# STM32MP21_CA35 register map
File version: 0.4
CPU: CM33 r0p1, little endian, MPU, FPU, vendor SysTick, 8 interrupt priority bits
Registers are 32-bit, read-write, reset 0x0 unless marked. A register's access mark holds for its fields unless they carry their own. Offsets are from the block's base; [hi:lo] are bit positions; {n}, {i} and the like mark numbered series; 'fields as' and 'values as' point back to an identical list.

## TIM15 — TIM15 address block description
Base 0x40250000
Same registers: TIM15_S 0x50250000
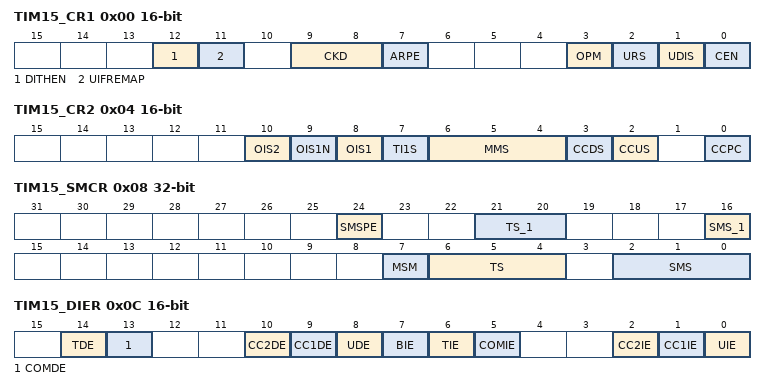
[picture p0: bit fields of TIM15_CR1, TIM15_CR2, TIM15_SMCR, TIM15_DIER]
0x00 TIM15_CR1 16-bit — TIM15 control register 1
  [12] DITHEN — Dithering enable
    0=Dithering disabled; 1=Dithering enabled
  [11] UIFREMAP — UIF status bit remapping
    0=No remapping; 1=Remapping enabled
  [9:8] CKD — Clock division
    0=tless thansub>DTS less than/sub>= tless thansub>tim_ker_ckless than/sub>; 1=tless thansub>DTSless than/sub> = 2*tless thansub>tim_ker_ckless than/sub>; 2=tless thansub>DTSless than/sub> = 4*tless thansub>tim_ker_ckless than/sub>
  [7] ARPE — Auto-reload preload enable
    0=TIM15_ARR register is not buffered; 1=TIM15_ARR register is buffered
  [3] OPM — One-pulse mode
    0=Counter is not stopped at update event; 1=Counter stops counting at the next update event (clearing the bit CEN)
  [2] URS — Update request source
    0=Any of the following events generate an update interrupt if enabled; 1=Only counter overflow/underflow generates an update interrupt if enabled
  [1] UDIS — Update disable
    0=UEV enabled; 1=UEV disabled
  [0] CEN — Counter enable
    0=Counter disabled; 1=Counter enabled
0x04 TIM15_CR2 16-bit — TIM15 control register 2
  [10] OIS2 — Output idle state 2 (tim_oc2 output)
    0=tim_oc2=0 when MOE=0; 1=tim_oc2=1 when MOE=0
  [9] OIS1N — Output Idle state 1 (tim_oc1n output)
    0=tim_oc1n=0 after a dead-time when MOE=0; 1=tim_oc1n=1 after a dead-time when MOE=0
  [8] OIS1 — Output Idle state 1 (tim_oc1 output)
    0=tim_oc1=0 after a dead-time when MOE=0; 1=tim_oc1=1 after a dead-time when MOE=0
  [7] TI1S — tim_ti1 selection
    0=The tim_ti1_in[15:0] multiplexer output is connected to tim_ti1 input; 1=The tim_ti1_in[15:0] and tim_ti2_in[15:0] multiplexers output are connected to the tim_ti1 input (XOR combination)
  [6:4] MMS — Master mode selection
    0=Reset - the UG bit from the TIM15_EGR register is used as trigger output (tim_trgo); 1=Enable - the Counter Enable signal CNT_EN is used as trigger output (tim_trgo); 2=Update - The update event is selected as trigger output (tim_trgo); 3=Compare Pulse - The trigger output send a positive pulse when the CC1IF flag is to be set (even if it was already high), as soon as a capture or a compare match occurred (tim_trgo); 4=Compare - tim_oc1refc signal is used as trigger output (tim_trgo); 5=Compare - tim_oc2refc signal is used as trigger output (tim_trgo)
  [3] CCDS — Capture/compare DMA selection
    0=CCx DMA request sent when CCx event occurs; 1=CCx DMA requests sent when update event occurs
  [2] CCUS — Capture/compare control update selection
    0=When capture/compare control bits are preloaded (CCPC=1), they are updated by setting the COMG bit only; 1=When capture/compare control bits are preloaded (CCPC=1), they are updated by setting the COMG bit or when an rising edge occurs on tim_trgi
  [0] CCPC — Capture/compare preloaded control
    0=CCxE, CCxNE and OCxM bits are not preloaded; 1=CCxE, CCxNE and OCxM bits are preloaded, after having been written, they are updated only when a commutation event (COM) occurs (COMG bit set or rising edge detected on tim_trgi, depending on the CCUS bit)
0x08 TIM15_SMCR — TIM15 slave mode control register
  [24] SMSPE — SMS preload enable
    0=SMS[3:0] bit field is not preloaded; 1=SMS[3:0] preload is enabled
  [21:20] TS_1 — TS[4:3]
  [16] SMS_1 — SMS[3]
  [7] MSM — Master/slave mode
    0=No action; 1=The effect of an event on the trigger input (tim_trgi) is delayed to allow a perfect synchronization between the current timer and its slaves (through tim_trgo)
  [6:4] TS — TS[2:0]: Trigger selection
    {v}=Internal Trigger {v} (tim_itr{v}) (v=0..3); 4=tim_ti1 Edge Detector (tim_ti1f_ed); 5=Filtered Timer Input 1 (tim_ti1fp1); 6=Filtered Timer Input 2 (tim_ti2fp2)
  [2:0] SMS — SMS[2:0]: Slave mode selection
    0=Slave mode disabled - if CEN = 1' then the prescaler is clocked directly by the internal clock; 4=Reset Mode - Rising edge of the selected trigger input (tim_trgi) reinitializes the counter and generates an update of the registers; 5=Gated Mode - The counter clock is enabled when the trigger input (tim_trgi) is high; 6=Trigger Mode - The counter starts at a rising edge of the trigger tim_trgi (but it is not reset); 7=External Clock Mode 1 - Rising edges of the selected trigger (tim_trgi) clock the counter
0x0C TIM15_DIER 16-bit — TIM15 DMA/interrupt enable register
  [14] TDE — Trigger DMA request enable
    0=Trigger DMA request disabled; 1=Trigger DMA request enabled
  [13] COMDE — COM DMA request enable
    0=COM DMA request disabled; 1=COM DMA request enabled
  [10] CC2DE — Capture/Compare 2 DMA request enable
    0=CC2 DMA request disabled; 1=CC2 DMA request enabled
  [9] CC1DE — Capture/Compare 1 DMA request enable
    0=CC1 DMA request disabled; 1=CC1 DMA request enabled
  [8] UDE — Update DMA request enable
    0=Update DMA request disabled; 1=Update DMA request enabled
  [7] BIE — Break interrupt enable
    0=Break interrupt disabled; 1=Break interrupt enabled
  [6] TIE — Trigger interrupt enable
    0=Trigger interrupt disabled; 1=Trigger interrupt enabled
  [5] COMIE — COM interrupt enable
    0=COM interrupt disabled; 1=COM interrupt enabled
  [2] CC2IE — Capture/Compare 2 interrupt enable
    0=CC2 interrupt disabled; 1=CC2 interrupt enabled
  [1] CC1IE — Capture/Compare 1 interrupt enable
    0=CC1 interrupt disabled; 1=CC1 interrupt enabled
  [0] UIE — Update interrupt enable
    0=Update interrupt disabled; 1=Update interrupt enabled
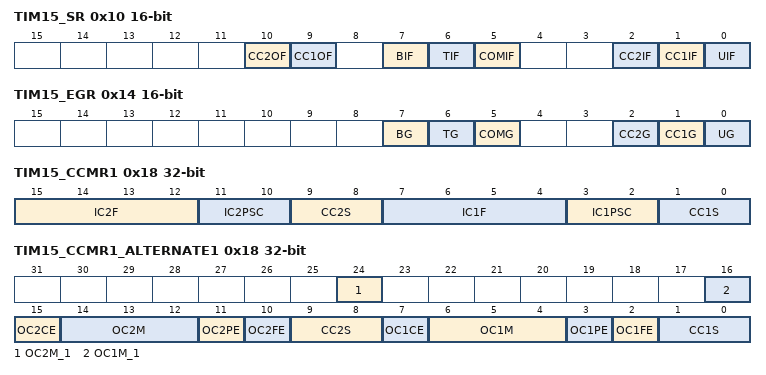
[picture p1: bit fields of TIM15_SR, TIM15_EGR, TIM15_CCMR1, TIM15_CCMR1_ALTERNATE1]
0x10 TIM15_SR 16-bit — TIM15 status register
  [10] CC2OF — Capture/Compare 2 overcapture flag
  [9] CC1OF — Capture/Compare 1 overcapture flag
    0=No overcapture has been detected; 1=The counter value has been captured in TIM15_CCR1 register while CC1IF flag was already set
  [7] BIF — Break interrupt flag
    0=No break event occurred; 1=An active level has been detected on the break input
  [6] TIF — Trigger interrupt flag
    0=No trigger event occurred; 1=Trigger interrupt pending
  [5] COMIF — COM interrupt flag
    0=No COM event occurred; 1=COM interrupt pending
  [2] CC2IF — Capture/Compare 2 interrupt flag
  [1] CC1IF — Capture/Compare 1 interrupt flag
    0=No compare match / No input capture occurred; 1=A compare match or an input capture occurred
  [0] UIF — Update interrupt flag
    0=No update occurred; 1=Update interrupt pending
0x14 TIM15_EGR 16-bit — TIM15 event generation register
  [7] BG wo — Break generation
    0=No action; 1=A break event is generated
  [6] TG wo — Trigger generation
    0=No action; 1=The TIF flag is set in TIM15_SR register
  [5] COMG — Capture/Compare control update generation
    0=No action; 1=When the CCPC bit is set, it is possible to update the CCxE, CCxNE and OCxM bits
  [2] CC2G wo — Capture/Compare 2 generation
  [1] CC1G wo — Capture/Compare 1 generation
    0=No action
  [0] UG wo — Update generation
    0=No action; 1=Reinitialize the counter and generates an update of the registers
0x18 TIM15_CCMR1 — TIM15 capture/compare mode register 1
  [15:12] IC2F — Input capture 2 filter
  [11:10] IC2PSC — Input capture 2 prescaler
  [9:8] CC2S — Capture/Compare 2 selection
    0=CC2 channel is configured as output; 1=CC2 channel is configured as input, tim_ic2 is mapped on tim_ti2; 2=CC2 channel is configured as input, tim_ic2 is mapped on tim_ti1; 3=CC2 channel is configured as input, tim_ic2 is mapped on tim_trc
  [7:4] IC1F — Input capture 1 filter
    0=No filter, sampling is done at fless thansub>DTSless than/sub>; 1=fless thansub>SAMPLINGless than/sub>=fless thansub>tim_ker_ckless than/sub>, N=2; 2=fless thansub>SAMPLINGless than/sub>=fless thansub>tim_ker_ckless than/sub>, N=4; 3=fless thansub>SAMPLINGless than/sub>=fless thansub>tim_ker_ckless than/sub>, N=8; 4=fless thansub>SAMPLINGless than/sub>=fless thansub>DTSless than/sub>/2, N=6; 5=fless thansub>SAMPLINGless than/sub>=fless thansub>DTSless than/sub>/2, N=8; 6=fless thansub>SAMPLINGless than/sub>=fless thansub>DTSless than/sub>/4, N=6; 7=fless thansub>SAMPLINGless than/sub>=fless thansub>DTSless than/sub>/4, N=8; 8=fless thansub>SAMPLINGless than/sub>=fless thansub>DTSless than/sub>/8, N=6; 9=fless thansub>SAMPLINGless than/sub>=fless thansub>DTSless than/sub>/8, N=8; 10=fless thansub>SAMPLINGless than/sub>=fless thansub>DTSless than/sub>/16, N=5; 11=fless thansub>SAMPLINGless than/sub>=fless thansub>DTSless than/sub>/16, N=6; 12=fless thansub>SAMPLINGless than/sub>=fless thansub>DTSless than/sub>/16, N=8; 13=fless thansub>SAMPLINGless than/sub>=fless thansub>DTSless than/sub>/32, N=5; 14=fless thansub>SAMPLINGless than/sub>=fless thansub>DTSless than/sub>/32, N=6; 15=fless thansub>SAMPLINGless than/sub>=fless thansub>DTSless than/sub>/32, N=8
  [3:2] IC1PSC — Input capture 1 prescaler
    0=no prescaler, capture is done each time an edge is detected on the capture input; 1=capture is done once every 2 events; 2=capture is done once every 4 events; 3=capture is done once every 8 events
  [1:0] CC1S — Capture/Compare 1 selection
    0=CC1 channel is configured as output; 1=CC1 channel is configured as input, tim_ic1 is mapped on tim_ti1; 2=CC1 channel is configured as input, tim_ic1 is mapped on tim_ti2; 3=CC1 channel is configured as input, tim_ic1 is mapped on tim_trc
0x18 TIM15_CCMR1_ALTERNATE1 (alternate view of TIM15_CCMR1) — TIM15 capture/compare mode register 1
  [24] OC2M_1 — OC2M[3]
  [16] OC1M_1 — OC1M[3]
  [15] OC2CE — Output compare 2 clear enable
  [14:12] OC2M — OC2M[2:0]: Output compare 2 mode
  [11] OC2PE — Output compare 2 preload enable
  [10] OC2FE — Output compare 2 fast enable
  [9:8] CC2S — Capture/Compare 2 selection
    0=CC2 channel is configured as output; 1=CC2 channel is configured as input, tim_ic2 is mapped on tim_ti2; 2=C2 channel is configured as input, tim_ic2 is mapped on tim_ti1; 3=CC2 channel is configured as input, tim_ic2 is mapped on tim_trc
  [7] OC1CE — Output compare 1 clear enable
    0=tim_oc1ref is not affected by the tim_ocref_clr_int input; 1=tim_oc1ref is cleared as soon as a High level is detected on tim_ocref_clr_int input
  [6:4] OC1M — OC1M[2:0]: Output compare 1 mode
    0=Frozen - The comparison between the output compare register TIM15_CCR1 and the counter TIM15_CNT has no effect on the outputs; 1=Set channel 1 to active level on match; 2=Set channel 1 to inactive level on match; 3=Toggle - tim_oc1ref toggles when TIM15_CNT=TIM15_CCR1; 4=Force inactive level - tim_oc1ref is forced low; 5=Force active level - tim_oc1ref is forced high; 6=PWM mode 1 - Channel 1 is active as long as TIM15_CNTless thanTIM15_CCR1 else inactive; 7=PWM mode 2 - Channel 1 is inactive as long as TIM15_CNTless thanTIM15_CCR1 else active
  [3] OC1PE — Output Compare 1 preload enable
    0=Preload register on TIM15_CCR1 disabled; 1=Preload register on TIM15_CCR1 enabled
  [2] OC1FE — Output Compare 1 fast enable
    0=CC1 behaves normally depending on counter and CCR1 values even when the trigger is ON; 1=An active edge on the trigger input acts like a compare match on CC1 output
  [1:0] CC1S — Capture/Compare 1 selection
    values as TIM15_CCMR1.CC1S
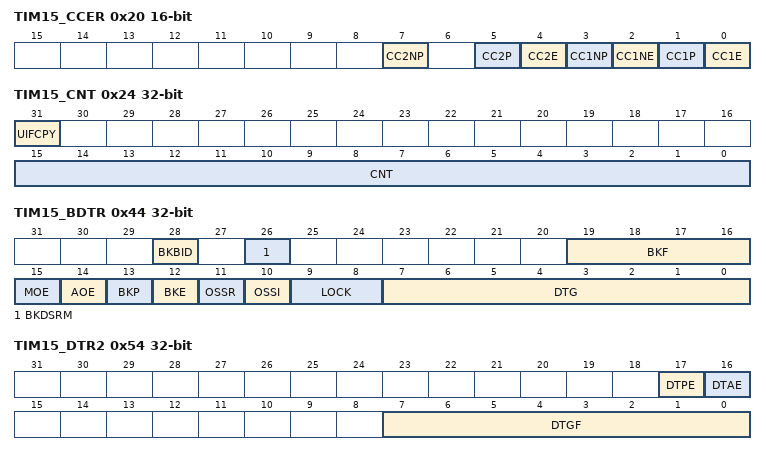
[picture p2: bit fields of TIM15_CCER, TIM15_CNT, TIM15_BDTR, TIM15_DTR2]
0x20 TIM15_CCER 16-bit — TIM15 capture/compare enable register
  [7] CC2NP — Capture/Compare 2 complementary output polarity
  [5] CC2P — Capture/Compare 2 output polarity
  [4] CC2E — Capture/Compare 2 output enable
  [3] CC1NP — Capture/Compare 1 complementary output polarity
    0=tim_oc1n active high; 1=tim_oc1n active low
  [2] CC1NE — Capture/Compare 1 complementary output enable
    0=Off - tim_oc1n is not active; 1=On - tim_oc1n signal is output on the corresponding output pin depending on MOE, OSSI, OSSR, OIS1, OIS1N and CC1E bits
  [1] CC1P — Capture/Compare 1 output polarity
    0=OC1 active high (output mode) / Edge sensitivity selection (input mode, see below); 1=OC1 active low (output mode) / Edge sensitivity selection (input mode, see below)
  [0] CC1E — Capture/Compare 1 output enable
    0=Capture mode disabled / OC1 is not active (see below); 1=Capture mode enabled / OC1 signal is output on the corresponding output pin
0x24 TIM15_CNT — TIM15 counter
  [31] UIFCPY ro — UIF Copy
  [15:0] CNT — Counter value
0x28 TIM15_PSC 16-bit — TIM15 prescaler
  [15:0] PSC — Prescaler value
0x2C TIM15_ARR reset 0xFFFF — TIM15 auto-reload register
  [19:0] ARR — Auto-reload value
0x30 TIM15_RCR 16-bit — TIM15 repetition counter register
  [7:0] REP — Repetition counter reload value
0x34 TIM15_CCR1 — TIM15 capture/compare register 1
  [19:0] CCR1 — Capture/compare 1 value
0x38 TIM15_CCR2 — TIM15 capture/compare register 2
  [19:0] CCR2 — Capture/compare 2 value
0x44 TIM15_BDTR — TIM15 break and dead-time register
  [28] BKBID — Break bidirectional
    0=Break input tim_brk in input mode; 1=Break input tim_brk in bidirectional mode
  [26] BKDSRM — Break disarm
    0=Break input tim_brk is armed; 1=Break input tim_brk is disarmed
  [19:16] BKF — Break filter
    0=No filter, tim_brk acts asynchronously; 1=fless thansub>SAMPLINGless than/sub>=fless thansub>tim_ker_ckless than/sub>, N=2; 2=fless thansub>SAMPLINGless than/sub>=fless thansub>tim_ker_ckless than/sub>, N=4; 3=fless thansub>SAMPLINGless than/sub>=fless thansub>tim_ker_ckless than/sub>, N=8; 4=fless thansub>SAMPLINGless than/sub>=fless thansub>DTSless than/sub>/2, N=6; 5=fless thansub>SAMPLINGless than/sub>=fless thansub>DTSless than/sub>/2, N=8; 6=fless thansub>SAMPLINGless than/sub>=fless thansub>DTSless than/sub>/4, N=6; 7=fless thansub>SAMPLINGless than/sub>=fless thansub>DTSless than/sub>/4, N=8; 8=fless thansub>SAMPLINGless than/sub>=fless thansub>DTSless than/sub>/8, N=6; 9=fless thansub>SAMPLINGless than/sub>=fless thansub>DTSless than/sub>/8, N=8; 10=fless thansub>SAMPLINGless than/sub>=fless thansub>DTSless than/sub>/16, N=5; 11=fless thansub>SAMPLINGless than/sub>=fless thansub>DTSless than/sub>/16, N=6; 12=fless thansub>SAMPLINGless than/sub>=fless thansub>DTSless than/sub>/16, N=8; 13=fless thansub>SAMPLINGless than/sub>=fless thansub>DTSless than/sub>/32, N=5; 14=fless thansub>SAMPLINGless than/sub>=fless thansub>DTSless than/sub>/32, N=6; 15=fless thansub>SAMPLINGless than/sub>=fless thansub>DTSless than/sub>/32, N=8
  [15] MOE — Main output enable
    0=tim_ocx and tim_ocxn outputs are disabled or forced to idle state depending on the OSSI bit; 1=tim_ocx and tim_ocxn outputs are enabled if their respective enable bits are set (CCxE, CCxNE in TIM15_CCER register)
  [14] AOE — Automatic output enable
    0=MOE can be set only by software; 1=MOE can be set by software or automatically at the next update event (if the break input is not be active)
  [13] BKP — Break polarity
    0=Break input tim_brk is active low; 1=Break input tim_brk is active high
  [12] BKE — Break enable
    0=Break inputs (tim_brk and tim_sys_brk clock failure event) disabled
  [11] OSSR — Off-state selection for Run mode
    0=When inactive, tim_ocx/tim_ocxn outputs are disabled (the timer releases the output control which is taken over by the GPIO, which forces a Hi-Z state); 1=When inactive, tim_ocx/tim_ocxn outputs are enabled with their inactive level as soon as CCxE=1 or CCxNE=1 (the output is still controlled by the timer)
  [10] OSSI — Off-state selection for Idle mode
    0=When inactive, tim_ocx/tim_ocxn outputs are disabled (tim_ocx/tim_ocxn enable output signal=0); 1=When inactive, tim_ocx/tim_ocxn outputs are forced first with their idle level as soon as CCxE=1 or CCxNE=1
  [9:8] LOCK — Lock configuration
    0=LOCK OFF - No bit is write protected; 1=LOCK Level 1 = DTG bits in TIM15_BDTR register, OISx and OISxN bits in TIM15_CR2 register and BKBID/BKE/BKP/AOE bits in TIM15_BDTR register can no longer be written; 2=LOCK Level 2 = LOCK Level 1 + CC Polarity bits (CCxP/CCxNP bits in TIM15_CCER register, as long as the related channel is configured in output through the CCxS bits) as well as OSSR and OSSI bits can no longer be written; 3=OCK Level 3 = LOCK Level 2 + CC Control bits (OCxM and OCxPE bits in TIM15_CCMRx registers, as long as the related channel is configured in output through the CCxS bits) can no longer be written
  [7:0] DTG — Dead-time generator setup
0x54 TIM15_DTR2 — TIM15 timer deadtime register 2
  [17] DTPE — Deadtime preload enable
    0=Deadtime value is not preloaded; 1=Deadtime value preload is enabled
  [16] DTAE — Deadtime asymmetric enable
    0=Deadtime on rising and falling edges are identical, and defined with DTG[7:0] register; 1=Deadtime on rising edge is defined with DTG[7:0] register and deadtime on falling edge is defined with DTGF[7:0] bits
  [7:0] DTGF — Dead-time falling edge generator setup
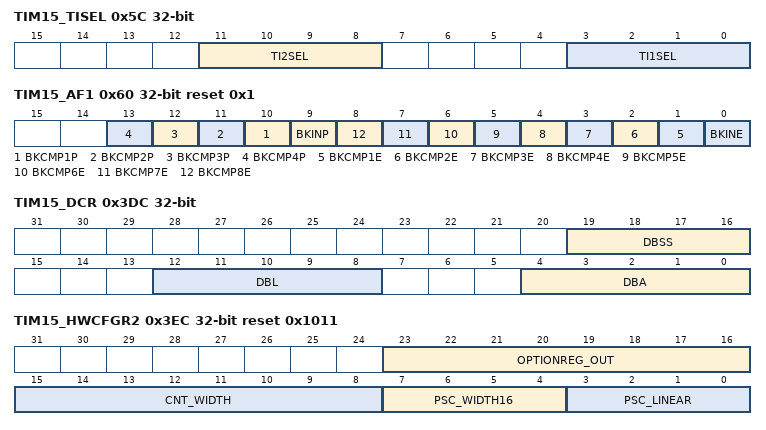
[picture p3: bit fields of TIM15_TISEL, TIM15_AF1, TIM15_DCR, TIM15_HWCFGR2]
0x5C TIM15_TISEL — TIM15 input selection register
  [11:8] TI2SEL — selects tim_ti2_in[15:0] input
    0=TIM15_CH2 input (tim_ti2_in0); 1=tim_ti2_in1; 15=tim_ti2_in15
  [3:0] TI1SEL — selects tim_ti1_in[15:0] input
    0=TIM15_CH1 input (tim_ti1_in0); 1=tim_ti1_in1; 15=tim_ti1_in15
0x60 TIM15_AF1 reset 0x1 — TIM15 alternate function register 1
  [n+9] BKCMP{n}P (n=1..4) — tim_brk_cmp{n} input polarity
    0=tim_brk_cmp{n} input is active high; 1=tim_brk_cmp{n} input is active low
  [9] BKINP — TIMx_BKIN input polarity
    0=TIMx_BKIN input is active high; 1=TIMx_BKIN input is active low
  [n] BKCMP{n}E (n=1..8) — tim_brk_cmp{n} enable
    0=tim_brk_cmp{n} input disabled; 1=tim_brk_cmp{n} input enabled
  [0] BKINE — TIMx_BKIN input enable
    0=TIMx_BKIN input disabled; 1=TIMx_BKIN input enabled
0x64 TIM15_AF2 — TIM15 alternate function register 2
  [18:16] OCRSEL — ocref_clr source selection
    {v}=tim_ocref_clr{v} (v=0..7)
0x3DC TIM15_DCR — TIM15 DMA control register
  [19:16] DBSS — DMA burst source selection
    1=Update; 2=CC1; 3=CC2; 6=COM; 7=Trigger
  [12:8] DBL — DMA burst length
    0=1 transfer,; 1=2 transfers,; 2=3 transfers,; 17=18 transfers
  [4:0] DBA — DMA base address
    0=TIM15_CR1,; 1=TIM15_CR2,; 2=TIM15_SMCR,
0x3E0 TIM15_DMAR — TIM15 DMA address for full transfer
  [31:0] DMAB — DMA register for burst accesses
0x3EC TIM15_HWCFGR2 ro reset 0x1011 — TIM15 hardware configuration 2 register
  [23:16] OPTIONREG_OUT — Option register number (0 to 16).
  [15:8] CNT_WIDTH — Counter width
    8=8-bits; 16=16-bits; 32=32-bits
  [7:4] PSC_WIDTH16 — Prescaler width
    0=7 (by power of 2) /8 (linear) -bit counter; 1=15 (by power of 2) /16 (linear) -bit counter
  [3:0] PSC_LINEAR — Prescaler linear
    0=prescaler by power of 2 (division by 1, 2, 4, 8; 1=prescaler is linear (division by 1, 2, 3, 4, 5
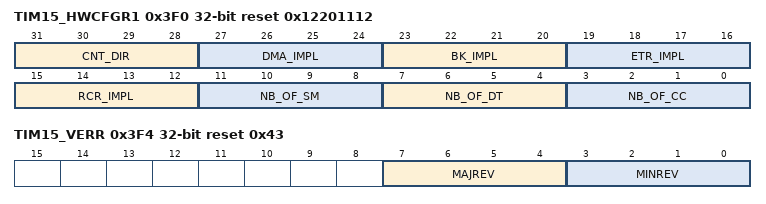
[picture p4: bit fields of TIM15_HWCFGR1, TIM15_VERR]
0x3F0 TIM15_HWCFGR1 ro reset 0x12201112 — TIM15 hardware configuration 1 register
  [31:28] CNT_DIR — Counter direction
    0=Down-counter only; 1=Up-counter only; 2=Up/Down counter allowing center-aligned mode
  [27:24] DMA_IMPL — DMA features implementation
    0=DMA requests are not possible; 1=Single DMA requests possible; 2=All DMA features implemented
  [23:20] BK_IMPL — Break circuit implementation
    0=no break implemented; 1=break1 implemented without filter (tim_brk + tim_sys_brk connected); 2=break1 implemented with filter (tim_brk + tim_sys_brk connected); 3=break 1 and 2 implemented (tim_brk + tim_sys_brk + brk2)
  [19:16] ETR_IMPL — External trigger implementation
    0=External trigger circuit not implemented, ocrefx cleared by ocref_clr input; 1=External trigger circuit implemented, ocrefx cleared by ocref_clr input; 2=External trigger circuit implemented, ocrefx cleared by etrf signal; 3=External trigger circuit implemented, ocrefx cleared by ocref_clr or etrf (1 control bit OCCS added in GPT_SMCR)
  [15:12] RCR_IMPL — Repetition counter implementation
    0=repetition counter not implemented; 1=8-bit repetition counter implemented; 2=16-bit repetition counter implemented
  [11:8] NB_OF_SM — Number of synchronization module
    0=synchronization module not implemented; 1=1 synchronization module implemented
  [7:4] NB_OF_DT — Number of complementary outputs and dead-time generators
  [3:0] NB_OF_CC — Number of capture / compare channel
    0=no capture/compare channel implemented; 1=only CC1 channel is implemented; 2=CC1 and CC2 channels are implemented; 3=CC1, CC2 and CC3 channels are implemented; 4=CC1, CC2, CC3 and CC4 channels are implemented; 5=CC1, CC2, CC3, CC4 and CC5 channels are implemented; 6=CC1, CC2, CC3, CC4, CC5 and CC6 channels are implemented
0x3F4 TIM15_VERR ro reset 0x43 — TIM15 IP version register
  [7:4] MAJREV — Major revision number.
  [3:0] MINREV — Minor revision number.
0x3F8 TIM15_IPIDR ro reset 0x120002 — TIM15 IP identification register
  [31:0] ID — IP identification code.
0x3FC TIM15_SIDR ro reset 0xA3C5DD01 — TIM15 size ID register
  [31:0] SID — Offset in KB of the ID register base address from the IP base address.
    1=1KB offset
